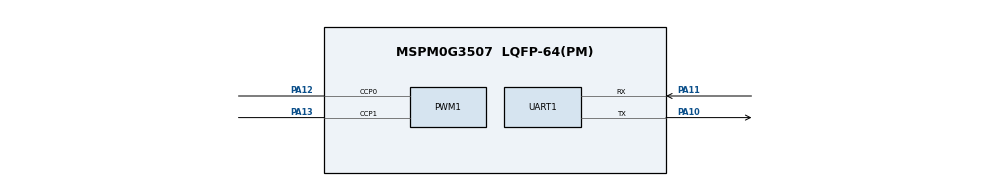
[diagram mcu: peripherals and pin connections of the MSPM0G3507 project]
/**
 * AI AGENTS: Do not edit this file directly. There is no validation or error feedback when
 * editing manually — mistakes will be silent until the file is loaded in SysConfig.
 * Use the SysConfig MCP server instead to make changes with immediate error reporting.
 *
 * These arguments were used when this file was generated. They will be automatically applied on subsequent loads
 * via the GUI or CLI. Run CLI with '--help' for additional information on how to override these arguments.
 * @cliArgs --device "MSPM0G350X" --part "Default" --package "LQFP-64(PM)" --product "mspm0_sdk@2.11.00.07"
 * @v2CliArgs --device "MSPM0G3507" --package "LQFP-64(PM)" --product "mspm0_sdk@2.11.00.07"
 * @versions {"tool":"1.28.0+4696"}
 */

/**
 * Import the modules used in this configuration.
 */
const GPIO   = scripting.addModule("/ti/driverlib/GPIO", {}, false);
const GPIO1  = GPIO.addInstance();
const PWM    = scripting.addModule("/ti/driverlib/PWM", {}, false);
const PWM1   = PWM.addInstance();
const SYSCTL = scripting.addModule("/ti/driverlib/SYSCTL");
const TIMER  = scripting.addModule("/ti/driverlib/TIMER", {}, false);
const TIMER1 = TIMER.addInstance();
const UART   = scripting.addModule("/ti/driverlib/UART", {}, false);
const UART1  = UART.addInstance();

/**
 * Write custom configuration values to the imported modules.
 */
GPIO1.$name                                 = "GPIO_MOTOR_A";
GPIO1.associatedPins.create(4);
GPIO1.associatedPins[0].$name               = "AIN_1";
GPIO1.associatedPins[0].assignedPortSegment = "Lower";
GPIO1.associatedPins[0].assignedPort        = "PORTB";
GPIO1.associatedPins[0].assignedPin         = "6";
GPIO1.associatedPins[1].$name               = "AIN_2";
GPIO1.associatedPins[1].assignedPort        = "PORTB";
GPIO1.associatedPins[1].assignedPin         = "7";
GPIO1.associatedPins[1].assignedPortSegment = "Lower";
GPIO1.associatedPins[2].$name               = "EA_1";
GPIO1.associatedPins[2].assignedPort        = "PORTB";
GPIO1.associatedPins[2].assignedPin         = "0";
GPIO1.associatedPins[2].direction           = "INPUT";
GPIO1.associatedPins[2].internalResistor    = "PULL_UP";
GPIO1.associatedPins[3].assignedPort        = "PORTB";
GPIO1.associatedPins[3].assignedPin         = "1";
GPIO1.associatedPins[3].internalResistor    = "PULL_UP";
GPIO1.associatedPins[3].direction           = "INPUT";
GPIO1.associatedPins[3].$name               = "EB_1";
GPIO1.associatedPins[3].polarity            = "RISE_FALL";
GPIO1.associatedPins[3].interruptEn         = true;

const Board = scripting.addModule("/ti/driverlib/Board", {}, false);

PWM1.$name                              = "PWM_MOTOR_A";
PWM1.clockDivider                       = 8;
PWM1.clockPrescale                      = 40;
PWM1.timerCount                         = 100;
PWM1.peripheral.$assign                 = "TIMG0";
PWM1.peripheral.ccp0Pin.$assign         = "PA12";
PWM1.peripheral.ccp1Pin.$assign         = "PA13";
PWM1.PWM_CHANNEL_0.$name                = "ti_driverlib_pwm_PWMTimerCC0";
PWM1.PWM_CHANNEL_1.$name                = "ti_driverlib_pwm_PWMTimerCC1";
PWM1.ccp0PinConfig.$name                = "ti_driverlib_gpio_GPIOPinGeneric0";
PWM1.ccp0PinConfig.direction            = scripting.forceWrite("OUTPUT");
PWM1.ccp0PinConfig.hideOutputInversion  = scripting.forceWrite(false);
PWM1.ccp0PinConfig.onlyInternalResistor = scripting.forceWrite(false);
PWM1.ccp0PinConfig.passedPeripheralType = scripting.forceWrite("Digital");
PWM1.ccp1PinConfig.$name                = "ti_driverlib_gpio_GPIOPinGeneric1";
PWM1.ccp1PinConfig.direction            = scripting.forceWrite("OUTPUT");
PWM1.ccp1PinConfig.hideOutputInversion  = scripting.forceWrite(false);
PWM1.ccp1PinConfig.onlyInternalResistor = scripting.forceWrite(false);
PWM1.ccp1PinConfig.passedPeripheralType = scripting.forceWrite("Digital");

SYSCTL.forceDefaultClkConfig = true;

TIMER1.$name       = "TIMER_PID";
TIMER1.interrupts  = ["ZERO"];
TIMER1.timerPeriod = "10ms";
TIMER1.timerClkDiv = 5;
TIMER1.timerMode   = "PERIODIC";

UART1.$name                    = "UART_0";
UART1.enabledInterrupts        = ["RX"];
UART1.targetBaudRate           = 115200;
UART1.peripheral.rxPin.$assign = "PA11";
UART1.peripheral.txPin.$assign = "PA10";
UART1.txPinConfig.$name        = "ti_driverlib_gpio_GPIOPinGeneric2";
UART1.rxPinConfig.$name        = "ti_driverlib_gpio_GPIOPinGeneric3";

/**
 * Pinmux solution for unlocked pins/peripherals. This ensures that minor changes to the automatic solver in a future
 * version of the tool will not impact the pinmux you originally saw.  These lines can be completely deleted in order to
 * re-solve from scratch.
 */
GPIO1.associatedPins[0].pin.$suggestSolution = "PB6";
GPIO1.associatedPins[1].pin.$suggestSolution = "PB7";
GPIO1.associatedPins[2].pin.$suggestSolution = "PB0";
GPIO1.associatedPins[3].pin.$suggestSolution = "PB1";
Board.peripheral.$suggestSolution            = "DEBUGSS";
Board.peripheral.swclkPin.$suggestSolution   = "PA20";
Board.peripheral.swdioPin.$suggestSolution   = "PA19";
SYSCTL.peripheral.$suggestSolution           = "SYSCTL";
TIMER1.peripheral.$suggestSolution           = "TIMA0";
UART1.peripheral.$suggestSolution            = "UART0";
